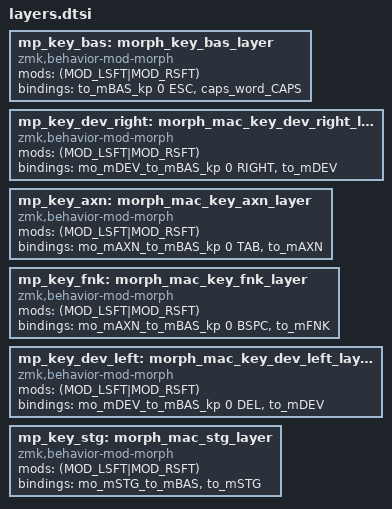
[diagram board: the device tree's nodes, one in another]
// tap:      escape      
// long-tap: to BAS layer
// shift:    caps lock
mp_key_bas: morph_key_bas_layer {
    compatible = "zmk,behavior-mod-morph";
    #binding-cells = <0>;
    mods = <(MOD_LSFT|MOD_RSFT)>;
    bindings = <&to_mBAS_kp 0 ESC>, <&caps_word_CAPS>;
};

// tap:      right arrow       
// long-tap: to DEV momentary
// shift:    to DEV layer
mp_key_dev_right: morph_mac_key_dev_right_layer {
    compatible = "zmk,behavior-mod-morph";
    #binding-cells = <0>;
    mods = <(MOD_LSFT|MOD_RSFT)>;
    bindings = <&mo_mDEV_to_mBAS_kp 0 RIGHT>, <&to_mDEV>;
};

// tap:      tab       
// long-tap: to AXN momentary
// shift:    to AXN layer
mp_key_axn: morph_mac_key_axn_layer {
    compatible = "zmk,behavior-mod-morph";
    #binding-cells = <0>;
    mods = <(MOD_LSFT|MOD_RSFT)>;
    bindings = <&mo_mAXN_to_mBAS_kp 0 TAB>, <&to_mAXN>;
};

// tap:      backspace       
// long-tap: to AXN momentary
// shift:    to FNK layer
mp_key_fnk: morph_mac_key_fnk_layer {
    compatible = "zmk,behavior-mod-morph";
    #binding-cells = <0>;
    mods = <(MOD_LSFT|MOD_RSFT)>;
    bindings = <&mo_mAXN_to_mBAS_kp 0 BSPC>, <&to_mFNK>;
};

// tap:      delete    
// long-tap: to DEV momentary
// shift:    to DEV layer
mp_key_dev_left: morph_mac_key_dev_left_layer {
    compatible = "zmk,behavior-mod-morph";
    #binding-cells = <0>;
    mods = <(MOD_LSFT|MOD_RSFT)>;
    bindings = <&mo_mDEV_to_mBAS_kp 0 DEL>, <&to_mDEV>;
};

// long-tap: to STG momentary
// shift:    to STG layer
mp_key_stg: morph_mac_stg_layer {
    compatible = "zmk,behavior-mod-morph";
    #binding-cells = <0>;
    mods = <(MOD_LSFT|MOD_RSFT)>;
    bindings = <&mo_mSTG_to_mBAS>, <&to_mSTG>;
};

